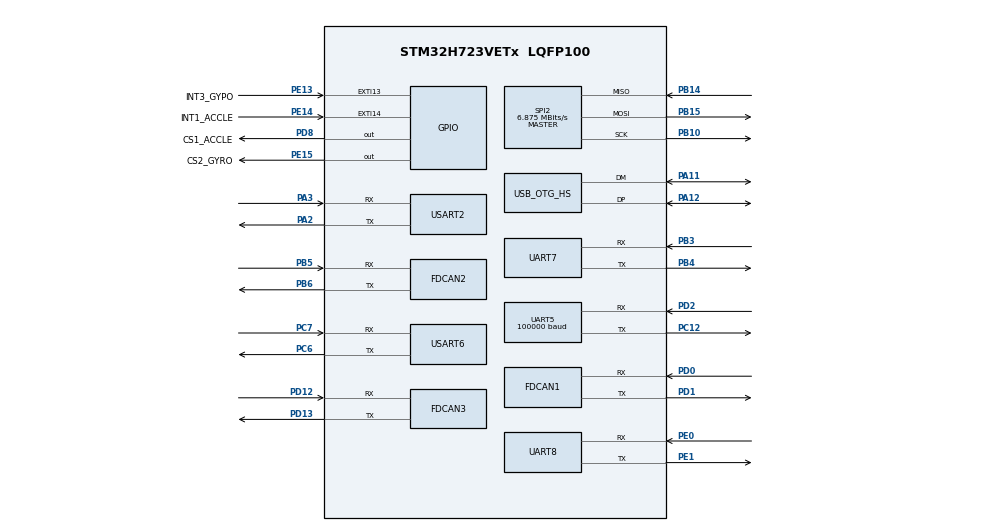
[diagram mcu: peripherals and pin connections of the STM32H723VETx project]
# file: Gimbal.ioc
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CORTEX_M7.default_mode_Activation=1
FDCAN1.CalculateBaudRateNominal=1000000
FDCAN1.CalculateTimeBitNominal=1000
FDCAN1.CalculateTimeQuantumNominal=50.0
FDCAN1.DataPrescaler=1
FDCAN1.DataSyncJumpWidth=1
FDCAN1.DataTimeSeg1=1
FDCAN1.DataTimeSeg2=1
FDCAN1.ExtFiltersNbr=0
FDCAN1.NominalPrescaler=5
FDCAN1.NominalSyncJumpWidth=4
FDCAN1.NominalTimeSeg1=15
FDCAN1.NominalTimeSeg2=4
FDCAN1.RxFifo0ElmtsNbr=8
FDCAN1.RxFifo1ElmtsNbr=0
FDCAN1.StdFiltersNbr=4
FDCAN1.TxFifoQueueElmtsNbr=8
FDCAN2.CalculateBaudRateNominal=1000000
FDCAN2.CalculateTimeBitNominal=1000
FDCAN2.CalculateTimeQuantumNominal=50.0
FDCAN2.ExtFiltersNbr=0
FDCAN2.NominalPrescaler=5
FDCAN2.NominalSyncJumpWidth=4
FDCAN2.NominalTimeSeg1=15
FDCAN2.NominalTimeSeg2=4
FDCAN2.RxFifo0ElmtsNbr=8
FDCAN2.RxFifo1ElmtsNbr=0
FDCAN2.StdFiltersNbr=4
FDCAN3.CalculateBaudRateNominal=1000000
FDCAN3.CalculateTimeBitNominal=1000
FDCAN3.CalculateTimeQuantumNominal=50.0
FDCAN3.NominalPrescaler=5
FDCAN3.NominalSyncJumpWidth=4
FDCAN3.NominalTimeSeg1=15
FDCAN3.NominalTimeSeg2=4
FDCAN3.RxFifo0ElmtsNbr=8
FDCAN3.StdFiltersNbr=4
FREERTOS.Tasks01=defaultTask,24,256,StartDefaultTask,Default,NULL,Dynamic,NULL,NULL
Mcu.Family=STM32H7
Mcu.Name=STM32H723VETx
Mcu.Package=LQFP100
NVIC.EXTI15_10_IRQn=true\:5\:0\:false\:false\:true\:true\:true\:true\:true
NVIC.FDCAN1_IT0_IRQn=true\:5\:0\:false\:false\:true\:true\:true\:true\:true
NVIC.FDCAN1_IT1_IRQn=true\:5\:0\:false\:false\:true\:true\:true\:true\:true
NVIC.FDCAN2_IT0_IRQn=true\:5\:0\:false\:false\:true\:true\:true\:true\:true
NVIC.FDCAN2_IT1_IRQn=true\:5\:0\:false\:false\:true\:true\:true\:true\:true
NVIC.FDCAN3_IT0_IRQn=true\:5\:0\:false\:false\:true\:true\:true\:true\:true
NVIC.FDCAN3_IT1_IRQn=true\:5\:0\:false\:false\:true\:true\:true\:true\:true
NVIC.OTG_HS_IRQn=true\:5\:0\:false\:false\:true\:true\:true\:true\:true
NVIC.PriorityGroup=NVIC_PRIORITYGROUP_4
NVIC.SPI2_IRQn=true\:5\:0\:false\:false\:true\:true\:true\:true\:true
NVIC.TIM23_IRQn=true\:15\:0\:false\:false\:true\:false\:false\:true\:true
NVIC.TimeBase=TIM23_IRQn
NVIC.TimeBaseIP=TIM23
NVIC.UART5_IRQn=true\:5\:0\:false\:false\:true\:true\:true\:true\:true
NVIC.UART7_IRQn=true\:5\:0\:false\:false\:true\:true\:true\:true\:true
NVIC.UART8_IRQn=true\:5\:0\:false\:false\:true\:true\:true\:true\:true
NVIC.USART2_IRQn=true\:5\:0\:false\:false\:true\:true\:true\:true\:true
NVIC.USART6_IRQn=true\:5\:0\:false\:false\:true\:true\:true\:true\:true
PA10.Signal=USB_OTG_HS_ID
PA11.Mode=Device_Only_FS
PA11.Signal=USB_OTG_HS_DM
PA12.Mode=Device_Only_FS
PA12.Signal=USB_OTG_HS_DP
PA13(JTMS/SWDIO).Mode=Serial_Wire
PA13(JTMS/SWDIO).Signal=DEBUG_JTMS-SWDIO
PA14(JTCK/SWCLK).Mode=Serial_Wire
PA14(JTCK/SWCLK).Signal=DEBUG_JTCK-SWCLK
PA2.Mode=Asynchronous
PA2.Signal=USART2_TX
PA3.Mode=Asynchronous
PA3.Signal=USART2_RX
PB10.Mode=Full_Duplex_Master
PB10.Signal=SPI2_SCK
PB14.Mode=Full_Duplex_Master
PB14.Signal=SPI2_MISO
PB15.Mode=Full_Duplex_Master
PB15.Signal=SPI2_MOSI
PB3(JTDO/TRACESWO).Mode=Asynchronous
PB3(JTDO/TRACESWO).Signal=UART7_RX
PB4(NJTRST).Mode=Asynchronous
PB4(NJTRST).Signal=UART7_TX
PB5.Mode=FDCAN_Activate
PB5.Signal=FDCAN2_RX
PB6.Mode=FDCAN_Activate
PB6.Signal=FDCAN2_TX
PC12.Mode=Asynchronous
PC12.Signal=UART5_TX
PC6.Mode=Asynchronous
PC6.Signal=USART6_TX
PC7.Mode=Asynchronous
PC7.Signal=USART6_RX
PD0.Mode=FDCAN_Activate
PD0.Signal=FDCAN1_RX
PD1.Mode=FDCAN_Activate
PD1.Signal=FDCAN1_TX
PD12.Mode=FDCAN_Activate
PD12.Signal=FDCAN3_RX
PD13.Mode=FDCAN_Activate
PD13.Signal=FDCAN3_TX
PD2.Mode=Asynchronous
PD2.Signal=UART5_RX
PD8.GPIO_Label=CS1_ACCLE
PD8.PinState=GPIO_PIN_SET
PD8.Signal=GPIO_Output
PE0.Mode=Asynchronous
PE0.Signal=UART8_RX
PE1.Mode=Asynchronous
PE1.Signal=UART8_TX
PE13.GPIO_Label=INT3_GYPO
PE13.Signal=GPXTI13
PE14.GPIO_Label=INT1_ACCLE
PE14.Signal=GPXTI14
PE15.GPIO_Label=CS2_GYRO
PE15.PinState=GPIO_PIN_SET
PE15.Signal=GPIO_Output
PH0-OSC_IN.Mode=HSE-External-Oscillator
PH0-OSC_IN.Signal=RCC_OSC_IN
PH1-OSC_OUT.Mode=HSE-External-Oscillator
PH1-OSC_OUT.Signal=RCC_OSC_OUT
ProjectManager.HeapSize=0x200
ProjectManager.StackSize=0x400
ProjectManager.TargetToolchain=CMake
RCC.ADCFreq_Value=100000000
RCC.APB1Freq_Value=137500000
RCC.APB2Freq_Value=137500000
RCC.APB3Freq_Value=137500000
RCC.APB4Freq_Value=137500000
RCC.CortexFreq_Value=550000000
RCC.D1PPRE=RCC_APB3_DIV2
RCC.D2PPRE1=RCC_APB1_DIV2
RCC.D2PPRE2=RCC_APB2_DIV2
RCC.D3PPRE=RCC_APB4_DIV2
RCC.DIVM1=3
RCC.DIVM2=6
RCC.DIVN1=68
RCC.DIVN2=50
RCC.DIVP1=1
RCC.DIVQ1=5
RCC.FDCANCLockSelection=RCC_FDCANCLKSOURCE_PLL2
RCC.FLatency-AdvancedSettings=FLASH_LATENCY_3
RCC.HCLKFreq_Value=275000000
RCC.HPRE=RCC_HCLK_DIV2
RCC.HSE_VALUE=24000000
RCC.PLL2FRACN=0
RCC.PLL2_VCO_SEL-AdvancedSettings=RCC_PLL2VCOMEDIUM
RCC.PLL3FRACN=0
RCC.PLLFRACN=6144
RCC.PLLSourceVirtual=RCC_PLLSOURCE_HSE
RCC.SYSCLKFreq_VALUE=550000000
RCC.SYSCLKSource=RCC_SYSCLKSOURCE_PLLCLK
RCC.USBCLockSelection=RCC_USBCLKSOURCE_HSI48
RCC.USBFreq_Value=48000000
SPI2.BaudRatePrescaler=SPI_BAUDRATEPRESCALER_16
SPI2.CalculateBaudRate=6.875 MBits/s
SPI2.DataSize=SPI_DATASIZE_8BIT
SPI2.Direction=SPI_DIRECTION_2LINES
SPI2.Mode=SPI_MODE_MASTER
SPI2.NSSPMode=SPI_NSS_PULSE_DISABLE
SPI2.VirtualType=VM_MASTER
TIM1.Channel-PWM\ Generation1\ No\ Output=TIM_CHANNEL_1
UART5.BaudRate=100000
USART2.VirtualMode-Asynchronous=VM_ASYNC
USART6.VirtualMode=VM_ASYNC
USB_DEVICE.CLASS_NAME_HS=CDC
USB_DEVICE.VirtualMode=Cdc
USB_DEVICE.VirtualModeHS=Cdc_HS
USB_OTG_HS.VirtualMode-Device_Only_FS=Device_Only_FS
VP_FREERTOS_VS_CMSIS_V2.Mode=CMSIS_V2
VP_MEMORYMAP_VS_MEMORYMAP.Mode=CurAppReg
VP_SYS_VS_tim23.Mode=TIM23
VP_TIM1_VS_ClockSourceINT.Mode=Internal
VP_TIM1_VS_no_output1.Mode=PWM Generation1 No Output
VP_USB_DEVICE_VS_USB_DEVICE_CDC_HS.Mode=CDC_HS
board=custom

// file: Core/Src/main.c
/* USER CODE BEGIN Header */
/**
  ******************************************************************************
  * @file           : main.c
  * @brief          : Main program body
  ******************************************************************************
  * @attention
  *
  * Copyright (c) 2026 STMicroelectronics.
  * All rights reserved.
  *
  * This software is licensed under terms that can be found in the LICENSE file
  * in the root directory of this software component.
  * If no LICENSE file comes with this software, it is provided AS-IS.
  *
  ******************************************************************************
  */
/* USER CODE END Header */
#include "main.h"
#include "FreeRTOS.h"
#include "cmsis_os2.h"
#include "fdcan.h"
#include "spi.h"
#include "tim.h"
#include "usart.h"
#include "usb_device.h"
#include "gpio.h"

void SystemClock_Config(void);
void PeriphCommonClock_Config(void);
static void MPU_Config(void);
void MX_FREERTOS_Init(void);

int main(void)
{

  /* MPU Configuration--------------------------------------------------------*/
  MPU_Config();

  /* MCU Configuration--------------------------------------------------------*/

  /* Reset of all peripherals, Initializes the Flash interface and the Systick. */
  HAL_Init();

  /* Configure the system clock */
  SystemClock_Config();

  /* Configure the peripherals common clocks */
  PeriphCommonClock_Config();

  /* Initialize all configured peripherals */
  MX_GPIO_Init();
  MX_FDCAN1_Init();
  MX_FDCAN2_Init();
  MX_FDCAN3_Init();
  MX_SPI2_Init();
  MX_UART5_Init();
  MX_UART7_Init();
  MX_UART8_Init();
  MX_USART2_UART_Init();
  MX_USART6_UART_Init();
  MX_TIM1_Init();

  /* Init scheduler */
  osKernelInitialize();  /* Call init function for freertos objects (in cmsis_os2.c) */
  MX_FREERTOS_Init();

  /* Start scheduler */
  osKernelStart();

  /* We should never get here as control is now taken by the scheduler */

  /* Infinite loop */
  while (1)
  {

  }
}

void SystemClock_Config(void)
{
  RCC_OscInitTypeDef RCC_OscInitStruct = {0};
  RCC_ClkInitTypeDef RCC_ClkInitStruct = {0};

  /** Supply configuration update enable
  */
  HAL_PWREx_ConfigSupply(PWR_LDO_SUPPLY);

  /** Configure the main internal regulator output voltage
  */
  __HAL_PWR_VOLTAGESCALING_CONFIG(PWR_REGULATOR_VOLTAGE_SCALE0);

  while(!__HAL_PWR_GET_FLAG(PWR_FLAG_VOSRDY)) {}

  /** Initializes the RCC Oscillators according to the specified parameters
  * in the RCC_OscInitTypeDef structure.
  */
  RCC_OscInitStruct.OscillatorType = RCC_OSCILLATORTYPE_HSI48|RCC_OSCILLATORTYPE_HSE;
  RCC_OscInitStruct.HSEState = RCC_HSE_ON;
  RCC_OscInitStruct.HSI48State = RCC_HSI48_ON;
  RCC_OscInitStruct.PLL.PLLState = RCC_PLL_ON;
  RCC_OscInitStruct.PLL.PLLSource = RCC_PLLSOURCE_HSE;
  RCC_OscInitStruct.PLL.PLLM = 3;
  RCC_OscInitStruct.PLL.PLLN = 68;
  RCC_OscInitStruct.PLL.PLLP = 1;
  RCC_OscInitStruct.PLL.PLLQ = 5;
  RCC_OscInitStruct.PLL.PLLR = 2;
  RCC_OscInitStruct.PLL.PLLRGE = RCC_PLL1VCIRANGE_3;
  RCC_OscInitStruct.PLL.PLLVCOSEL = RCC_PLL1VCOWIDE;
  RCC_OscInitStruct.PLL.PLLFRACN = 6144;
  if (HAL_RCC_OscConfig(&RCC_OscInitStruct) != HAL_OK)
  {
    Error_Handler();
  }

  /** Initializes the CPU, AHB and APB buses clocks
  */
  RCC_ClkInitStruct.ClockType = RCC_CLOCKTYPE_HCLK|RCC_CLOCKTYPE_SYSCLK
                              |RCC_CLOCKTYPE_PCLK1|RCC_CLOCKTYPE_PCLK2
                              |RCC_CLOCKTYPE_D3PCLK1|RCC_CLOCKTYPE_D1PCLK1;
  RCC_ClkInitStruct.SYSCLKSource = RCC_SYSCLKSOURCE_PLLCLK;
  RCC_ClkInitStruct.SYSCLKDivider = RCC_SYSCLK_DIV1;
  RCC_ClkInitStruct.AHBCLKDivider = RCC_HCLK_DIV2;
  RCC_ClkInitStruct.APB3CLKDivider = RCC_APB3_DIV2;
  RCC_ClkInitStruct.APB1CLKDivider = RCC_APB1_DIV2;
  RCC_ClkInitStruct.APB2CLKDivider = RCC_APB2_DIV2;
  RCC_ClkInitStruct.APB4CLKDivider = RCC_APB4_DIV2;

  if (HAL_RCC_ClockConfig(&RCC_ClkInitStruct, FLASH_LATENCY_3) != HAL_OK)
  {
    Error_Handler();
  }
}

void PeriphCommonClock_Config(void)
{
  RCC_PeriphCLKInitTypeDef PeriphClkInitStruct = {0};

  /** Initializes the peripherals clock
  */
  PeriphClkInitStruct.PeriphClockSelection = RCC_PERIPHCLK_FDCAN;
  PeriphClkInitStruct.PLL2.PLL2M = 6;
  PeriphClkInitStruct.PLL2.PLL2N = 50;
  PeriphClkInitStruct.PLL2.PLL2P = 2;
  PeriphClkInitStruct.PLL2.PLL2Q = 2;
  PeriphClkInitStruct.PLL2.PLL2R = 2;
  PeriphClkInitStruct.PLL2.PLL2RGE = RCC_PLL2VCIRANGE_2;
  PeriphClkInitStruct.PLL2.PLL2VCOSEL = RCC_PLL2VCOWIDE;
  PeriphClkInitStruct.PLL2.PLL2FRACN = 0;
  PeriphClkInitStruct.FdcanClockSelection = RCC_FDCANCLKSOURCE_PLL2;
  if (HAL_RCCEx_PeriphCLKConfig(&PeriphClkInitStruct) != HAL_OK)
  {
    Error_Handler();
  }
}

 /* MPU Configuration */

void MPU_Config(void)
{
  MPU_Region_InitTypeDef MPU_InitStruct = {0};

  /* Disables the MPU */
  HAL_MPU_Disable();

  /** Initializes and configures the Region and the memory to be protected
  */
  MPU_InitStruct.Enable = MPU_REGION_ENABLE;
  MPU_InitStruct.Number = MPU_REGION_NUMBER0;
  MPU_InitStruct.BaseAddress = 0x0;
  MPU_InitStruct.Size = MPU_REGION_SIZE_4GB;
  MPU_InitStruct.SubRegionDisable = 0x87;
  MPU_InitStruct.TypeExtField = MPU_TEX_LEVEL0;
  MPU_InitStruct.AccessPermission = MPU_REGION_NO_ACCESS;
  MPU_InitStruct.DisableExec = MPU_INSTRUCTION_ACCESS_DISABLE;
  MPU_InitStruct.IsShareable = MPU_ACCESS_SHAREABLE;
  MPU_InitStruct.IsCacheable = MPU_ACCESS_NOT_CACHEABLE;
  MPU_InitStruct.IsBufferable = MPU_ACCESS_NOT_BUFFERABLE;

  HAL_MPU_ConfigRegion(&MPU_InitStruct);
  /* Enables the MPU */
  HAL_MPU_Enable(MPU_PRIVILEGED_DEFAULT);

}

void HAL_TIM_PeriodElapsedCallback(TIM_HandleTypeDef *htim)
{
  if (htim->Instance == TIM23)
  {
    HAL_IncTick();
  }
}

void Error_Handler(void)
{
  __disable_irq();
  while (1)
  {
  }
}

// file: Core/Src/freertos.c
/* USER CODE BEGIN Header */
/**
  ******************************************************************************
  * File Name          : freertos.c
  * Description        : Code for freertos applications
  ******************************************************************************
  * @attention
  *
  * Copyright (c) 2026 STMicroelectronics.
  * All rights reserved.
  *
  * This software is licensed under terms that can be found in the LICENSE file
  * in the root directory of this software component.
  * If no LICENSE file comes with this software, it is provided AS-IS.
  *
  ******************************************************************************
  */
/* USER CODE END Header */

#include "FreeRTOS.h"
#include "task.h"
#include "main.h"
#include "FreeRTOS.h"
#include "cmsis_os2.h"

/* USER CODE BEGIN Includes */
#include "mytask.h"

/* USER CODE END Includes */

/* Definitions for defaultTask */
osThreadId_t defaultTaskHandle;
const osThreadAttr_t defaultTask_attributes = {
  .name = "defaultTask",
  .stack_size = 256 * 4,
  .priority = (osPriority_t) osPriorityNormal,
};

void StartDefaultTask(void *argument);

extern void MX_USB_DEVICE_Init(void);
void MX_FREERTOS_Init(void); /* (MISRA C 2004 rule 8.1) */

void MX_FREERTOS_Init(void) {

  /* Create the thread(s) */
  /* creation of defaultTask */
  defaultTaskHandle = osThreadNew(StartDefaultTask, NULL, &defaultTask_attributes);

}

void StartDefaultTask(void *argument)
{
  /* init code for USB_DEVICE */
  MX_USB_DEVICE_Init();
  /* USER CODE BEGIN StartDefaultTask */
  App_Control_Task(argument);
  /* USER CODE END StartDefaultTask */
}
